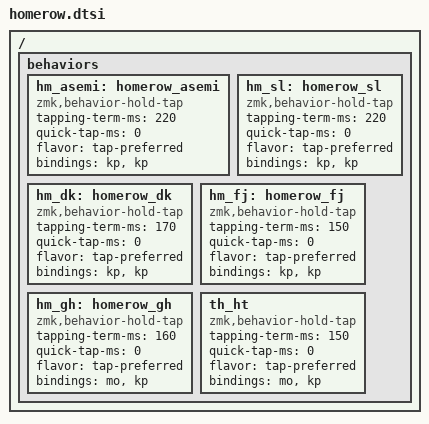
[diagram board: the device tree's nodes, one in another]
/ {
    behaviors {
        hm_asemi: homerow_asemi {
        compatible = "zmk,behavior-hold-tap";
        #binding-cells = <2>;
        tapping-term-ms = <220>;
        quick-tap-ms = <0>;
        flavor = "tap-preferred";
        bindings = <&kp>, <&kp>;
        };

        hm_sl: homerow_sl {
        compatible = "zmk,behavior-hold-tap";
        #binding-cells = <2>;
        tapping-term-ms = <220>;
        quick-tap-ms = <0>;
        flavor = "tap-preferred";
        bindings = <&kp>, <&kp>;
        };

        hm_dk: homerow_dk {
        compatible = "zmk,behavior-hold-tap";
        #binding-cells = <2>;
        tapping-term-ms = <170>;
        quick-tap-ms = <0>;
        flavor = "tap-preferred";
        bindings = <&kp>, <&kp>;
        };

        hm_fj: homerow_fj {
        compatible = "zmk,behavior-hold-tap";
        #binding-cells = <2>;
        tapping-term-ms = <150>;
        quick-tap-ms = <0>;
        flavor = "tap-preferred";
        bindings = <&kp>, <&kp>;
        };

        hm_gh: homerow_gh {
        compatible = "zmk,behavior-hold-tap";
        #binding-cells = <2>;
        tapping-term-ms = <160>;
        quick-tap-ms = <0>;
        flavor = "tap-preferred";
        bindings = <&mo>, <&kp>;
        };

        th_ht: th_ht {
        compatible = "zmk,behavior-hold-tap";
        #binding-cells = <2>;
        tapping-term-ms = <150>;
        quick-tap-ms = <0>;
        flavor = "tap-preferred";
        bindings = <&mo>, <&kp>;
        };

    };
};
